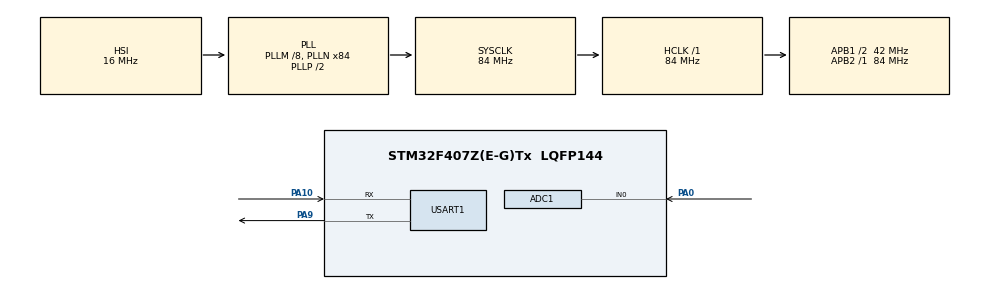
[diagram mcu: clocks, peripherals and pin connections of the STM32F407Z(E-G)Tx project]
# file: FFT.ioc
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ADC1.Channel-0\#ChannelRegularConversion=ADC_CHANNEL_0
ADC1.ExternalTrigConv=ADC_EXTERNALTRIGCONV_T3_TRGO
ADC1.NbrOfConversionFlag=1
ADC1.Rank-0\#ChannelRegularConversion=1
ADC1.SamplingTime-0\#ChannelRegularConversion=ADC_SAMPLETIME_3CYCLES
ADC1.master=1
Dma.ADC1.0.Direction=DMA_PERIPH_TO_MEMORY
Dma.ADC1.0.FIFOMode=DMA_FIFOMODE_DISABLE
Dma.ADC1.0.Instance=DMA2_Stream0
Dma.ADC1.0.MemDataAlignment=DMA_MDATAALIGN_HALFWORD
Dma.ADC1.0.MemInc=DMA_MINC_ENABLE
Dma.ADC1.0.Mode=DMA_NORMAL
Dma.ADC1.0.PeriphDataAlignment=DMA_PDATAALIGN_HALFWORD
Dma.ADC1.0.PeriphInc=DMA_PINC_DISABLE
Dma.ADC1.0.Priority=DMA_PRIORITY_LOW
Dma.Request0=ADC1
Mcu.Family=STM32F4
Mcu.Name=STM32F407Z(E-G)Tx
Mcu.Package=LQFP144
NVIC.DMA2_Stream0_IRQn=true\:0\:0\:false\:false\:true\:false\:true\:true
NVIC.PriorityGroup=NVIC_PRIORITYGROUP_4
PA0-WKUP.Signal=ADCx_IN0
PA10.Mode=Asynchronous
PA10.Signal=USART1_RX
PA13.Mode=Serial_Wire
PA13.Signal=SYS_JTMS-SWDIO
PA14.Mode=Serial_Wire
PA14.Signal=SYS_JTCK-SWCLK
PA9.Mode=Asynchronous
PA9.Signal=USART1_TX
PH0-OSC_IN.Mode=HSE-External-Oscillator
PH0-OSC_IN.Signal=RCC_OSC_IN
PH1-OSC_OUT.Mode=HSE-External-Oscillator
PH1-OSC_OUT.Signal=RCC_OSC_OUT
ProjectManager.HeapSize=0x200
ProjectManager.StackSize=0x400
ProjectManager.TargetToolchain=MDK-ARM V5.32
RCC.48MHZClocksFreq_Value=42000000
RCC.AHBFreq_Value=84000000
RCC.APB1CLKDivider=RCC_HCLK_DIV2
RCC.APB1Freq_Value=42000000
RCC.APB1TimFreq_Value=84000000
RCC.APB2Freq_Value=84000000
RCC.APB2TimFreq_Value=84000000
RCC.CortexFreq_Value=84000000
RCC.HCLKFreq_Value=84000000
RCC.HSE_VALUE=25000000
RCC.HSI_VALUE=16000000
RCC.LSE_VALUE=32768
RCC.PLLM=8
RCC.PLLN=84
RCC.SYSCLKFreq_VALUE=84000000
RCC.SYSCLKSource=RCC_SYSCLKSOURCE_PLLCLK
RCC.VCOOutputFreq_Value=168000000
SH.ADCx_IN0.0=ADC1_IN0,IN0
TIM3.AutoReloadPreload=TIM_AUTORELOAD_PRELOAD_ENABLE
TIM3.Period=82-1
TIM3.TIM_MasterOutputTrigger=TIM_TRGO_UPDATE
USART1.VirtualMode=VM_ASYNC
VP_TIM3_VS_ClockSourceINT.Mode=Internal
board=custom

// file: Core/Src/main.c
/* USER CODE BEGIN Header */
/**
  ******************************************************************************
  * @file           : main.c
  * @brief          : Main program body
  ******************************************************************************
  * @attention
  *
  * Copyright (c) 2025 STMicroelectronics.
  * All rights reserved.
  *
  * This software is licensed under terms that can be found in the LICENSE file
  * in the root directory of this software component.
  * If no LICENSE file comes with this software, it is provided AS-IS.
  *
  ******************************************************************************
  */
/* USER CODE END Header */
#include "main.h"
#include "adc.h"
#include "dma.h"
#include "tim.h"
#include "usart.h"
#include "gpio.h"

/* USER CODE BEGIN Includes */
#include "arm_math.h"
#include "arm_const_structs.h"
#include "stdio.h"
/* USER CODE END Includes */

/* USER CODE BEGIN PD */
#define FFT_LENGTH 1024
/* USER CODE END PD */

/* USER CODE BEGIN PV */
uint16_t adc_buff[200];//存放ADC采集的数据
/*
AdcConvEnd用来检测ADC是否采集完毕
0：没有采集完毕
1：采集完毕，在stm32f1xx_it里的DMA完成中断进行修改
 */
__IO uint8_t AdcConvEnd = 0;
uint16_t adcBuff[FFT_LENGTH];

float fft_inputbuf[FFT_LENGTH * 2];
float fft_outputbuf[FFT_LENGTH];

/* USER CODE END PV */

void SystemClock_Config(void);

int main(void)
{

  /* MCU Configuration--------------------------------------------------------*/

  /* Reset of all peripherals, Initializes the Flash interface and the Systick. */
  HAL_Init();

  /* Configure the system clock */
  SystemClock_Config();

  /* Initialize all configured peripherals */
  MX_GPIO_Init();
  MX_DMA_Init();
  MX_ADC1_Init();
  MX_TIM3_Init();
  MX_USART1_UART_Init();
  /* USER CODE BEGIN 2 */
HAL_ADC_Start_DMA(&hadc1, (uint32_t *)adcBuff, FFT_LENGTH);
HAL_TIM_Base_Start(&htim3);

while (!AdcConvEnd)       //等待转换完毕
	;
for (int i = 0; i < FFT_LENGTH; i++)
{
    fft_inputbuf[i * 2] = adcBuff[i] * 3.3 / 4096;//实部赋值，* 3.3 / 4096是为了将ADC采集到的值转换成实际电压
    fft_inputbuf[i * 2 + 1] = 0;//虚部赋值，固定为0.
}

arm_cfft_f32(&arm_cfft_sR_f32_len1024, fft_inputbuf, 0, 1);
arm_cmplx_mag_f32(fft_inputbuf, fft_outputbuf, FFT_LENGTH);
fft_outputbuf[0] /= 1024;

for (int i = 1; i < FFT_LENGTH; i++)//输出各次谐波幅值
{
    fft_outputbuf[i] /= 512;
}
printf("FFT Result:\r\n");

for (int i = 0; i < FFT_LENGTH; i++)//输出各次谐波幅值
{
	printf("%d:\t%.2f\r\n", i, fft_outputbuf[i]);
}

  /* USER CODE END 2 */

  /* Infinite loop */
  while (1)
  {

  }
}

void SystemClock_Config(void)
{
  RCC_OscInitTypeDef RCC_OscInitStruct = {0};
  RCC_ClkInitTypeDef RCC_ClkInitStruct = {0};

  /** Configure the main internal regulator output voltage
  */
  __HAL_RCC_PWR_CLK_ENABLE();
  __HAL_PWR_VOLTAGESCALING_CONFIG(PWR_REGULATOR_VOLTAGE_SCALE1);

  /** Initializes the RCC Oscillators according to the specified parameters
  * in the RCC_OscInitTypeDef structure.
  */
  RCC_OscInitStruct.OscillatorType = RCC_OSCILLATORTYPE_HSI;
  RCC_OscInitStruct.HSIState = RCC_HSI_ON;
  RCC_OscInitStruct.HSICalibrationValue = RCC_HSICALIBRATION_DEFAULT;
  RCC_OscInitStruct.PLL.PLLState = RCC_PLL_ON;
  RCC_OscInitStruct.PLL.PLLSource = RCC_PLLSOURCE_HSI;
  RCC_OscInitStruct.PLL.PLLM = 8;
  RCC_OscInitStruct.PLL.PLLN = 84;
  RCC_OscInitStruct.PLL.PLLP = RCC_PLLP_DIV2;
  RCC_OscInitStruct.PLL.PLLQ = 4;
  if (HAL_RCC_OscConfig(&RCC_OscInitStruct) != HAL_OK)
  {
    Error_Handler();
  }

  /** Initializes the CPU, AHB and APB buses clocks
  */
  RCC_ClkInitStruct.ClockType = RCC_CLOCKTYPE_HCLK|RCC_CLOCKTYPE_SYSCLK
                              |RCC_CLOCKTYPE_PCLK1|RCC_CLOCKTYPE_PCLK2;
  RCC_ClkInitStruct.SYSCLKSource = RCC_SYSCLKSOURCE_PLLCLK;
  RCC_ClkInitStruct.AHBCLKDivider = RCC_SYSCLK_DIV1;
  RCC_ClkInitStruct.APB1CLKDivider = RCC_HCLK_DIV2;
  RCC_ClkInitStruct.APB2CLKDivider = RCC_HCLK_DIV1;

  if (HAL_RCC_ClockConfig(&RCC_ClkInitStruct, FLASH_LATENCY_2) != HAL_OK)
  {
    Error_Handler();
  }
}

void Error_Handler(void)
{
  __disable_irq();
  while (1)
  {
  }
}
